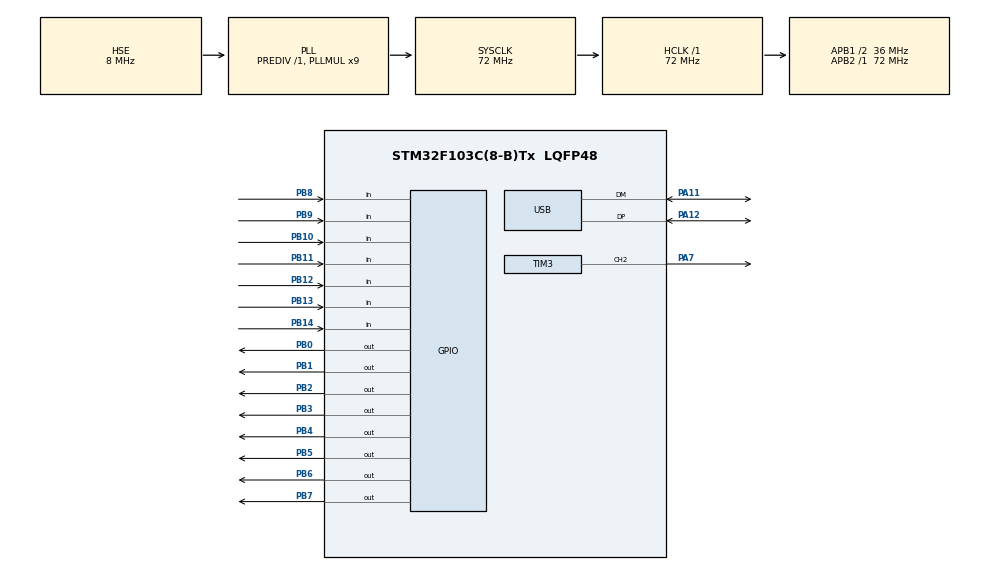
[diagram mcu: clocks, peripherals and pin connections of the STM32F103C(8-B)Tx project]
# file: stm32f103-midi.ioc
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Mcu.Family=STM32F1
Mcu.Name=STM32F103C(8-B)Tx
Mcu.Package=LQFP48
NVIC.PriorityGroup=NVIC_PRIORITYGROUP_4
PA11.Mode=Device
PA11.Signal=USB_DM
PA12.Mode=Device
PA12.Signal=USB_DP
PA13.Mode=Serial_Wire
PA13.Signal=SYS_JTMS-SWDIO
PA14.Mode=Serial_Wire
PA14.Signal=SYS_JTCK-SWCLK
PA7.Signal=S_TIM3_CH2
PB0.PinState=GPIO_PIN_SET
PB0.Signal=GPIO_Output
PB1.PinState=GPIO_PIN_SET
PB1.Signal=GPIO_Output
PB10.GPIO_PuPd=GPIO_PULLUP
PB10.Signal=GPIO_Input
PB11.GPIO_PuPd=GPIO_PULLUP
PB11.Signal=GPIO_Input
PB12.GPIO_PuPd=GPIO_PULLUP
PB12.Signal=GPIO_Input
PB13.GPIO_PuPd=GPIO_PULLUP
PB13.Signal=GPIO_Input
PB14.GPIO_PuPd=GPIO_PULLUP
PB14.Signal=GPIO_Input
PB2.PinState=GPIO_PIN_SET
PB2.Signal=GPIO_Output
PB3.PinState=GPIO_PIN_SET
PB3.Signal=GPIO_Output
PB4.PinState=GPIO_PIN_SET
PB4.Signal=GPIO_Output
PB5.PinState=GPIO_PIN_SET
PB5.Signal=GPIO_Output
PB6.PinState=GPIO_PIN_SET
PB6.Signal=GPIO_Output
PB7.PinState=GPIO_PIN_SET
PB7.Signal=GPIO_Output
PB8.GPIO_PuPd=GPIO_PULLUP
PB8.Signal=GPIO_Input
PB9.GPIO_PuPd=GPIO_PULLUP
PB9.Signal=GPIO_Input
PD0-OSC_IN.Mode=HSE-External-Oscillator
PD0-OSC_IN.Signal=RCC_OSC_IN
PD1-OSC_OUT.Mode=HSE-External-Oscillator
PD1-OSC_OUT.Signal=RCC_OSC_OUT
ProjectManager.HeapSize=0x200
ProjectManager.StackSize=0x400
ProjectManager.TargetToolchain=STM32CubeIDE
RCC.ADCPresc=RCC_ADCPCLK2_DIV6
RCC.AHBFreq_Value=72000000
RCC.APB1CLKDivider=RCC_HCLK_DIV2
RCC.APB1Freq_Value=36000000
RCC.APB1TimFreq_Value=72000000
RCC.APB2Freq_Value=72000000
RCC.APB2TimFreq_Value=72000000
RCC.HCLKFreq_Value=72000000
RCC.PLLMUL=RCC_PLL_MUL9
RCC.PLLSourceVirtual=RCC_PLLSOURCE_HSE
RCC.SYSCLKFreq_VALUE=72000000
RCC.SYSCLKSource=RCC_SYSCLKSOURCE_PLLCLK
RCC.USBFreq_Value=48000000
RCC.USBPrescaler=RCC_USBCLKSOURCE_PLL_DIV1_5
SH.S_TIM3_CH2.0=TIM3_CH2,PWM Generation2 CH2
TIM3.Channel-PWM\ Generation2\ CH2=TIM_CHANNEL_2
TIM3.Period=18000
TIM3.Pulse-PWM\ Generation2\ CH2=9000
VP_TIM3_VS_ClockSourceINT.Mode=Internal
board=custom

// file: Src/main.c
/* USER CODE BEGIN Header */
/**
  ******************************************************************************
  * @file           : main.c
  * @brief          : Main program body
  ******************************************************************************
  * @attention
  *
  * <h2><center>&copy; Copyright (c) 2020 STMicroelectronics.
  * All rights reserved.</center></h2>
  *
  * This software component is licensed by ST under BSD 3-Clause license,
  * the "License"; You may not use this file except in compliance with the
  * License. You may obtain a copy of the License at:
  *                        opensource.org/licenses/BSD-3-Clause
  *
  ******************************************************************************
  */
/* USER CODE END Header */
#include "main.h"

/* USER CODE BEGIN Includes */
#include "startup.h"
#include "Sound/usb_device.h"
#include "Sound/usbd_midi_if.h"
/* USER CODE END Includes */

TIM_HandleTypeDef htim3;

PCD_HandleTypeDef hpcd_USB_FS;

void SystemClock_Config(void);
static void MX_GPIO_Init(void);
static void MX_USB_PCD_Init(void);
static void MX_TIM3_Init(void);

int main(void)
{

  /* MCU Configuration--------------------------------------------------------*/

  /* Reset of all peripherals, Initializes the Flash interface and the Systick. */
  HAL_Init();

  /* Configure the system clock */
  SystemClock_Config();

  /* USER CODE BEGIN SysInit */
	initialize();
  /* USER CODE END SysInit */

  /* Initialize all configured peripherals */
  MX_GPIO_Init();
  MX_USB_PCD_Init();
  MX_TIM3_Init();
  /* USER CODE BEGIN 2 */

  // USB MIDI
  HAL_NVIC_SetPriority(USB_LP_CAN1_RX0_IRQn, 2, 0);
  HAL_NVIC_EnableIRQ(USB_LP_CAN1_RX0_IRQn);
  MX_USB_DEVICE_Init();

  /* USER CODE END 2 */

  /* Infinite loop */
  /* USER CODE BEGIN WHILE */
  while (1)
  {
    keypad_scan();
    /* USER CODE END WHILE */

  }
}

void SystemClock_Config(void)
{
  RCC_OscInitTypeDef RCC_OscInitStruct = {0};
  RCC_ClkInitTypeDef RCC_ClkInitStruct = {0};
  RCC_PeriphCLKInitTypeDef PeriphClkInit = {0};

  /** Initializes the RCC Oscillators according to the specified parameters
  * in the RCC_OscInitTypeDef structure.
  */
  RCC_OscInitStruct.OscillatorType = RCC_OSCILLATORTYPE_HSE;
  RCC_OscInitStruct.HSEState = RCC_HSE_ON;
  RCC_OscInitStruct.HSEPredivValue = RCC_HSE_PREDIV_DIV1;
  RCC_OscInitStruct.HSIState = RCC_HSI_ON;
  RCC_OscInitStruct.PLL.PLLState = RCC_PLL_ON;
  RCC_OscInitStruct.PLL.PLLSource = RCC_PLLSOURCE_HSE;
  RCC_OscInitStruct.PLL.PLLMUL = RCC_PLL_MUL9;
  if (HAL_RCC_OscConfig(&RCC_OscInitStruct) != HAL_OK)
  {
    Error_Handler();
  }
  /** Initializes the CPU, AHB and APB buses clocks
  */
  RCC_ClkInitStruct.ClockType = RCC_CLOCKTYPE_HCLK|RCC_CLOCKTYPE_SYSCLK
                              |RCC_CLOCKTYPE_PCLK1|RCC_CLOCKTYPE_PCLK2;
  RCC_ClkInitStruct.SYSCLKSource = RCC_SYSCLKSOURCE_PLLCLK;
  RCC_ClkInitStruct.AHBCLKDivider = RCC_SYSCLK_DIV1;
  RCC_ClkInitStruct.APB1CLKDivider = RCC_HCLK_DIV2;
  RCC_ClkInitStruct.APB2CLKDivider = RCC_HCLK_DIV1;

  if (HAL_RCC_ClockConfig(&RCC_ClkInitStruct, FLASH_LATENCY_2) != HAL_OK)
  {
    Error_Handler();
  }
  PeriphClkInit.PeriphClockSelection = RCC_PERIPHCLK_USB;
  PeriphClkInit.UsbClockSelection = RCC_USBCLKSOURCE_PLL_DIV1_5;
  if (HAL_RCCEx_PeriphCLKConfig(&PeriphClkInit) != HAL_OK)
  {
    Error_Handler();
  }
}

static void MX_TIM3_Init(void)
{

  TIM_ClockConfigTypeDef sClockSourceConfig = {0};
  TIM_MasterConfigTypeDef sMasterConfig = {0};
  TIM_OC_InitTypeDef sConfigOC = {0};

  htim3.Instance = TIM3;
  htim3.Init.Prescaler = 0;
  htim3.Init.CounterMode = TIM_COUNTERMODE_UP;
  htim3.Init.Period = 18000;
  htim3.Init.ClockDivision = TIM_CLOCKDIVISION_DIV1;
  htim3.Init.AutoReloadPreload = TIM_AUTORELOAD_PRELOAD_DISABLE;
  if (HAL_TIM_Base_Init(&htim3) != HAL_OK)
  {
    Error_Handler();
  }
  sClockSourceConfig.ClockSource = TIM_CLOCKSOURCE_INTERNAL;
  if (HAL_TIM_ConfigClockSource(&htim3, &sClockSourceConfig) != HAL_OK)
  {
    Error_Handler();
  }
  if (HAL_TIM_PWM_Init(&htim3) != HAL_OK)
  {
    Error_Handler();
  }
  sMasterConfig.MasterOutputTrigger = TIM_TRGO_RESET;
  sMasterConfig.MasterSlaveMode = TIM_MASTERSLAVEMODE_DISABLE;
  if (HAL_TIMEx_MasterConfigSynchronization(&htim3, &sMasterConfig) != HAL_OK)
  {
    Error_Handler();
  }
  sConfigOC.OCMode = TIM_OCMODE_PWM1;
  sConfigOC.Pulse = 9000;
  sConfigOC.OCPolarity = TIM_OCPOLARITY_HIGH;
  sConfigOC.OCFastMode = TIM_OCFAST_DISABLE;
  if (HAL_TIM_PWM_ConfigChannel(&htim3, &sConfigOC, TIM_CHANNEL_2) != HAL_OK)
  {
    Error_Handler();
  }
  HAL_TIM_MspPostInit(&htim3);

}

static void MX_USB_PCD_Init(void)
{

  hpcd_USB_FS.Instance = USB;
  hpcd_USB_FS.Init.dev_endpoints = 8;
  hpcd_USB_FS.Init.speed = PCD_SPEED_FULL;
  hpcd_USB_FS.Init.low_power_enable = DISABLE;
  hpcd_USB_FS.Init.lpm_enable = DISABLE;
  hpcd_USB_FS.Init.battery_charging_enable = DISABLE;
  if (HAL_PCD_Init(&hpcd_USB_FS) != HAL_OK)
  {
    Error_Handler();
  }

}

static void MX_GPIO_Init(void)
{
  GPIO_InitTypeDef GPIO_InitStruct = {0};

  /* GPIO Ports Clock Enable */
  __HAL_RCC_GPIOD_CLK_ENABLE();
  __HAL_RCC_GPIOA_CLK_ENABLE();
  __HAL_RCC_GPIOB_CLK_ENABLE();

  /*Configure GPIO pin Output Level */
  HAL_GPIO_WritePin(GPIOB, GPIO_PIN_0|GPIO_PIN_1|GPIO_PIN_2|GPIO_PIN_3
                          |GPIO_PIN_4|GPIO_PIN_5|GPIO_PIN_6|GPIO_PIN_7, GPIO_PIN_SET);

  /*Configure GPIO pins : PB0 PB1 PB2 PB3
                           PB4 PB5 PB6 PB7 */
  GPIO_InitStruct.Pin = GPIO_PIN_0|GPIO_PIN_1|GPIO_PIN_2|GPIO_PIN_3
                          |GPIO_PIN_4|GPIO_PIN_5|GPIO_PIN_6|GPIO_PIN_7;
  GPIO_InitStruct.Mode = GPIO_MODE_OUTPUT_PP;
  GPIO_InitStruct.Pull = GPIO_NOPULL;
  GPIO_InitStruct.Speed = GPIO_SPEED_FREQ_LOW;
  HAL_GPIO_Init(GPIOB, &GPIO_InitStruct);

  /*Configure GPIO pins : PB10 PB11 PB12 PB13
                           PB14 PB8 PB9 */
  GPIO_InitStruct.Pin = GPIO_PIN_10|GPIO_PIN_11|GPIO_PIN_12|GPIO_PIN_13
                          |GPIO_PIN_14|GPIO_PIN_8|GPIO_PIN_9;
  GPIO_InitStruct.Mode = GPIO_MODE_INPUT;
  GPIO_InitStruct.Pull = GPIO_PULLUP;
  HAL_GPIO_Init(GPIOB, &GPIO_InitStruct);

}

void Error_Handler(void)
{
}

/************************ (C) COPYRIGHT STMicroelectronics *****END OF FILE****/
